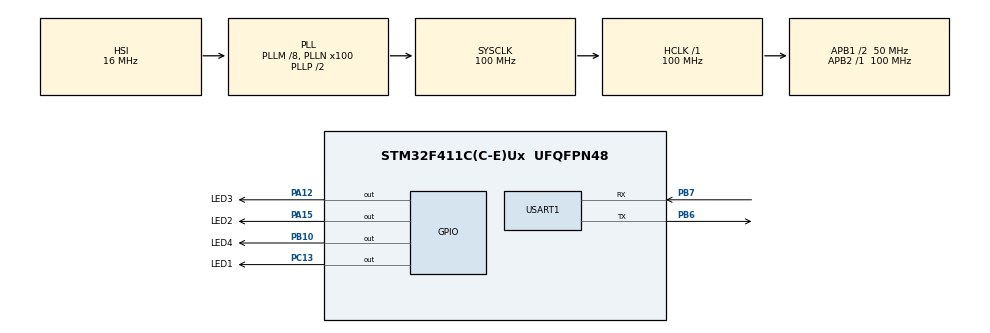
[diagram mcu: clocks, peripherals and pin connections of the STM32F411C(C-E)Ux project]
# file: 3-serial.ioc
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Mcu.Family=STM32F4
Mcu.Name=STM32F411C(C-E)Ux
Mcu.Package=UFQFPN48
NVIC.PriorityGroup=NVIC_PRIORITYGROUP_4
PA12.GPIO_Label=LED3
PA12.PinState=GPIO_PIN_RESET
PA12.Signal=GPIO_Output
PA15.GPIO_Label=LED2
PA15.PinState=GPIO_PIN_RESET
PA15.Signal=GPIO_Output
PB10.GPIO_Label=LED4
PB10.PinState=GPIO_PIN_RESET
PB10.Signal=GPIO_Output
PB6.Mode=Asynchronous
PB6.Signal=USART1_TX
PB7.Mode=Asynchronous
PB7.Signal=USART1_RX
PC13-ANTI_TAMP.GPIO_Label=LED1
PC13-ANTI_TAMP.PinState=GPIO_PIN_RESET
PC13-ANTI_TAMP.Signal=GPIO_Output
ProjectManager.HeapSize=0x200
ProjectManager.StackSize=0x400
ProjectManager.TargetToolchain=MDK-ARM V5
RCC.48MHZClocksFreq_Value=50000000
RCC.AHBFreq_Value=100000000
RCC.APB1CLKDivider=RCC_HCLK_DIV2
RCC.APB1Freq_Value=50000000
RCC.APB1TimFreq_Value=100000000
RCC.APB2Freq_Value=100000000
RCC.APB2TimFreq_Value=100000000
RCC.CortexFreq_Value=100000000
RCC.HCLKFreq_Value=100000000
RCC.HSE_VALUE=25000000
RCC.HSI_VALUE=16000000
RCC.LSE_VALUE=32768
RCC.PLLM=8
RCC.PLLN=100
RCC.SYSCLKFreq_VALUE=100000000
RCC.SYSCLKSource=RCC_SYSCLKSOURCE_PLLCLK
RCC.VCOOutputFreq_Value=200000000
USART1.VirtualMode=VM_ASYNC
board=custom

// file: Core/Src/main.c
/* USER CODE BEGIN Header */
/**
  ******************************************************************************
  * @file           : main.c
  * @brief          : Main program body
  ******************************************************************************
  * @attention
  *
  * <h2><center>&copy; Copyright (c) 2019 STMicroelectronics.
  * All rights reserved.</center></h2>
  *
  * This software component is licensed by ST under BSD 3-Clause license,
  * the "License"; You may not use this file except in compliance with the
  * License. You may obtain a copy of the License at:
  *                        opensource.org/licenses/BSD-3-Clause
  *
  ******************************************************************************
  */
/* USER CODE END Header */

#include "main.h"
#include "usart.h"
#include "gpio.h"

void SystemClock_Config(void);

int main(void)
{

  /* MCU Configuration--------------------------------------------------------*/

  /* Reset of all peripherals, Initializes the Flash interface and the Systick. */
  HAL_Init();

  /* Configure the system clock */
  SystemClock_Config();

  /* Initialize all configured peripherals */
  MX_GPIO_Init();
  MX_USART1_UART_Init();
  /* USER CODE BEGIN 2 */
	uint8_t rbuf[10];
  /* USER CODE END 2 */

  /* Infinite loop */
    while (1)
    {

    /* USER CODE BEGIN 3 */
        HAL_UART_Receive(&huart1, rbuf, 10, 999999);
		while (1);
		HAL_UART_Transmit(&huart1, "Hello World\n", 12, 999);
        HAL_Delay(1000);

    }
  /* USER CODE END 3 */
}

void SystemClock_Config(void)
{
  RCC_OscInitTypeDef RCC_OscInitStruct = {0};
  RCC_ClkInitTypeDef RCC_ClkInitStruct = {0};

  /** Configure the main internal regulator output voltage
  */
  __HAL_RCC_PWR_CLK_ENABLE();
  __HAL_PWR_VOLTAGESCALING_CONFIG(PWR_REGULATOR_VOLTAGE_SCALE1);
  /** Initializes the CPU, AHB and APB busses clocks
  */
  RCC_OscInitStruct.OscillatorType = RCC_OSCILLATORTYPE_HSI;
  RCC_OscInitStruct.HSIState = RCC_HSI_ON;
  RCC_OscInitStruct.HSICalibrationValue = RCC_HSICALIBRATION_DEFAULT;
  RCC_OscInitStruct.PLL.PLLState = RCC_PLL_ON;
  RCC_OscInitStruct.PLL.PLLSource = RCC_PLLSOURCE_HSI;
  RCC_OscInitStruct.PLL.PLLM = 8;
  RCC_OscInitStruct.PLL.PLLN = 100;
  RCC_OscInitStruct.PLL.PLLP = RCC_PLLP_DIV2;
  RCC_OscInitStruct.PLL.PLLQ = 4;
  if (HAL_RCC_OscConfig(&RCC_OscInitStruct) != HAL_OK)
  {
    Error_Handler();
  }
  /** Initializes the CPU, AHB and APB busses clocks
  */
  RCC_ClkInitStruct.ClockType = RCC_CLOCKTYPE_HCLK|RCC_CLOCKTYPE_SYSCLK
                              |RCC_CLOCKTYPE_PCLK1|RCC_CLOCKTYPE_PCLK2;
  RCC_ClkInitStruct.SYSCLKSource = RCC_SYSCLKSOURCE_PLLCLK;
  RCC_ClkInitStruct.AHBCLKDivider = RCC_SYSCLK_DIV1;
  RCC_ClkInitStruct.APB1CLKDivider = RCC_HCLK_DIV2;
  RCC_ClkInitStruct.APB2CLKDivider = RCC_HCLK_DIV1;

  if (HAL_RCC_ClockConfig(&RCC_ClkInitStruct, FLASH_LATENCY_3) != HAL_OK)
  {
    Error_Handler();
  }
}

void Error_Handler(void)
{
}

/************************ (C) COPYRIGHT STMicroelectronics *****END OF FILE****/
